# f28p65x_icl_xbar_regs register map
Vendor: Texas Instruments
Peripheral module from a debugger description file (folder C2000).
Address unit: 16 bits
Registers are 16-bit, read-write, no defined reset value unless marked. A register's access mark holds for its fields unless they carry their own. Offsets are as the file gives them; lines under a group give offsets from that group; [hi:lo] are bit positions; {n}, {i} and the like mark numbered series; 'fields as' and 'values as' point back to an identical list; <NAME> marks a mode.

## ICL_XBAR_REGS — ICL XBAR Registers
0x00 ICL1SELECT — ICL1SELECT Input Select Register
  [15:0] SELECT — Select INPUT for ICL1 signal
0x01 ICL2SELECT — ICL2SELECT Input Select Register
  [15:0] SELECT — Select INPUT for ICL2 signal
0x02 ICL3SELECT — ICL3SELECT Input Select Register
  [15:0] SELECT — Select INPUT for ICL3 signal
0x03 ICL4SELECT — ICL4SELECT Input Select Register
  [15:0] SELECT — Select INPUT for ICL4 signal
0x04 ICL5SELECT — ICL5SELECT Input Select Register
  [15:0] SELECT — Select INPUT for ICL5 signal
0x05 ICL6SELECT — ICL6SELECT Input Select Register
  [15:0] SELECT — Select INPUT for ICL6 signal
0x06 ICL7SELECT — ICL7SELECT Input Select Register
  [15:0] SELECT — Select INPUT for ICL7 signal
0x07 ICL8SELECT — ICL8SELECT Input Select Register
  [15:0] SELECT — Select INPUT for ICL8 signal
0x08 ICL9SELECT — ICL9SELECT Input Select Register
  [15:0] SELECT — Select INPUT for ICL9 signal
0x09 ICL10SELECT — ICL10SELECT Input Select Register
  [15:0] SELECT — Select INPUT for ICL10 signal
0x0A ICL11SELECT — ICL11SELECT Input Select Register
  [15:0] SELECT — Select INPUT for ICL11 signal
0x0B ICL12SELECT — ICL12SELECT Input Select Register
  [15:0] SELECT — Select INPUT for ICL12 signal
0x0C ICL13SELECT — ICL13SELECT Input Select Register
  [15:0] SELECT — Select INPUT for ICL13 signal
0x0D ICL14SELECT — ICL14SELECT Input Select Register
  [15:0] SELECT — Select INPUT for ICL14 signal
0x0E ICL15SELECT — ICL15SELECT Input Select Register
  [15:0] SELECT — Select INPUT for ICL15 signal
0x0F ICL16SELECT — ICL16SELECT Input Select Register
  [15:0] SELECT — Select INPUT for ICL16 signal
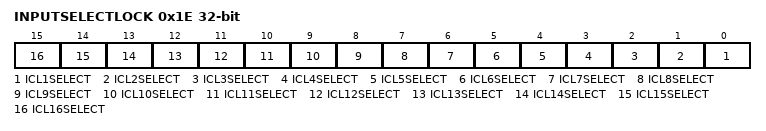
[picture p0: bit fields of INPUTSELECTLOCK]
0x1E INPUTSELECTLOCK 32-bit
  [n-1] ICL{n}SELECT (n=1..16) — Lock bit for ICL{n}SELECT Register
